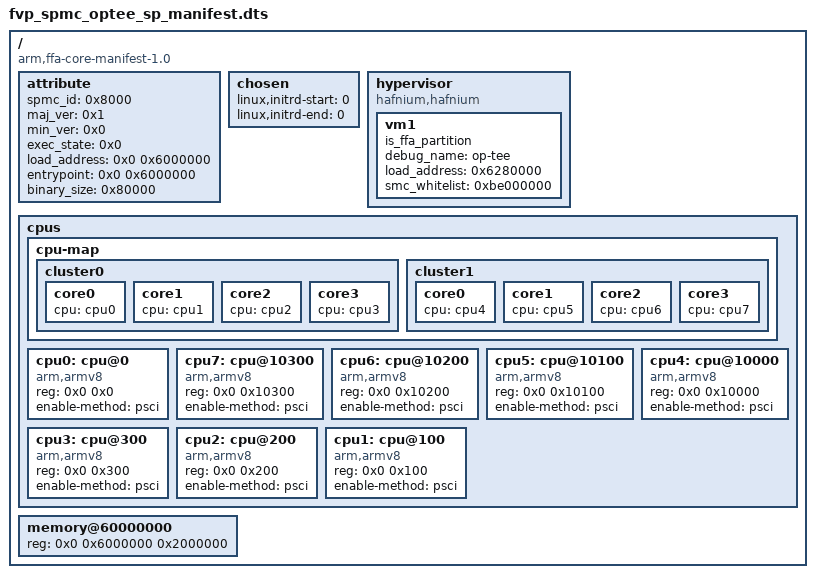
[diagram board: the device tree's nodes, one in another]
/*
 * Copyright (c) 2020, Arm Limited. All rights reserved.
 *
 * SPDX-License-Identifier: BSD-3-Clause
 */
/dts-v1/;

/ {
	compatible = "arm,ffa-core-manifest-1.0";
	#address-cells = <2>;
	#size-cells = <1>;

	attribute {
		spmc_id = <0x8000>;
		maj_ver = <0x1>;
		min_ver = <0x0>;
		exec_state = <0x0>;
		load_address = <0x0 0x6000000>;
		entrypoint = <0x0 0x6000000>;
		binary_size = <0x80000>;
	};

	chosen {
		linux,initrd-start = <0>;
		linux,initrd-end = <0>;
	};

	hypervisor {
		compatible = "hafnium,hafnium";
		vm1 {
			is_ffa_partition;
			debug_name = "op-tee";
			load_address = <0x6280000>;
			smc_whitelist = <0xbe000000>;
		};
	};

	cpus {
		#address-cells = <0x2>;
		#size-cells = <0x0>;

		cpu-map {
			cluster0 {
				core0 {
					cpu = <&cpu0>;
				};
				core1 {
					cpu = <&cpu1>;
				};
				core2 {
					cpu = <&cpu2>;
				};
				core3 {
					cpu = <&cpu3>;
				};
			};

			cluster1 {
				core0 {
					cpu = <&cpu4>;
				};
				core1 {
					cpu = <&cpu5>;
				};
				core2 {
					cpu = <&cpu6>;
				};
				core3 {
					cpu = <&cpu7>;
				};
			};
		};

		cpu0: cpu@0 {
			device_type = "cpu";
			compatible = "arm,armv8";
			reg = <0x0 0x0>;
			enable-method = "psci";
		};

		/* SPM requires cpu nodes are declared in descending order */
		cpu7: cpu@10300 {
			device_type = "cpu";
			compatible = "arm,armv8";
			reg = <0x0 0x10300>;
			enable-method = "psci";
		};

		cpu6: cpu@10200 {
			device_type = "cpu";
			compatible = "arm,armv8";
			reg = <0x0 0x10200>;
			enable-method = "psci";
		};

		cpu5: cpu@10100 {
			device_type = "cpu";
			compatible = "arm,armv8";
			reg = <0x0 0x10100>;
			enable-method = "psci";
		};

		cpu4: cpu@10000 {
			device_type = "cpu";
			compatible = "arm,armv8";
			reg = <0x0 0x10000>;
			enable-method = "psci";
		};

		cpu3: cpu@300 {
			device_type = "cpu";
			compatible = "arm,armv8";
			reg = <0x0 0x300>;
			enable-method = "psci";
		};

		cpu2: cpu@200 {
			device_type = "cpu";
			compatible = "arm,armv8";
			reg = <0x0 0x200>;
			enable-method = "psci";
		};

		cpu1: cpu@100 {
			device_type = "cpu";
			compatible = "arm,armv8";
			reg = <0x0 0x100>;
			enable-method = "psci";
		};
	};

	memory@60000000 {
		device_type = "memory";
		reg = <0x0 0x6000000 0x2000000>; /* Trusted DRAM */
	};
};
